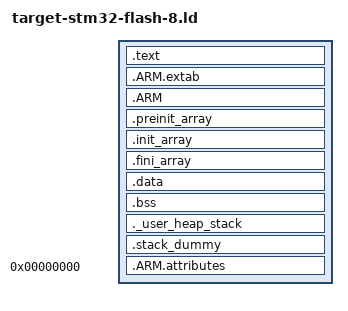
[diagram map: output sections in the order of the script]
/* Linker script to configure memory regions. 
 * Need modifying for a specific board. 
 *   FLASH.ORIGIN: starting address of flash
 *   FLASH.LENGTH: length of flash
 *   RAM.ORIGIN: starting address of RAM bank 0
 *   RAM.LENGTH: length of RAM bank 0
 */


/* Linker script to place sections and symbol values. Should be used together
 * with other linker script that defines memory regions FLASH and RAM.
 * It references following symbols, which must be defined in code:
 *   Reset_Handler : Entry of reset handler
 * 
 * It defines following symbols, which code can use without definition:
 *   __exidx_start
 *   __exidx_end
 *   __copy_table_start__
 *   __copy_table_end__
 *   __zero_table_start__
 *   __zero_table_end__
 *   __etext
 *   __data_start__
 *   __preinit_array_start
 *   __preinit_array_end
 *   __init_array_start
 *   __init_array_end
 *   __fini_array_start
 *   __fini_array_end
 *   __data_end__
 *   __bss_start__
 *   __bss_end__
 *   __end__
 *   end
 *   __HeapLimit
 *   __StackLimit
 *   __StackTop
 *   __stack
 */

ENTRY(Reset_Handler)

/* Highest address of the user mode stack */
_estack = 0x20020000;    /* end of 128K RAM on AHB bus*/

/* Generate a link error if heap and stack don't fit into RAM */
_Min_Heap_Size = 0;      /* required amount of heap  */
_Min_Stack_Size = 0x400; /* required amount of stack */

/* Define output sections */
SECTIONS
{
  /* The program code and other data goes into FLASH */
  .text :
  {
    . 	= ALIGN(8);
	KEEP(*(.isr_vector))
        *(.text)           /* .text sections (code) */

        KEEP (*(.init))
        KEEP (*(.fini))

	/* .ctors */
	*crtbegin.o(.ctors)
	*crtbegin?.o(.ctors)
	*(EXCLUDE_FILE(*crtend?.o *crtend.o) .ctors)
	*(SORT(.ctors.*))
	*(.ctors)

	/* .dtors */
 	*crtbegin.o(.dtors)
 	*crtbegin?.o(.dtors)
 	*(EXCLUDE_FILE(*crtend?.o *crtend.o) .dtors)
 	*(SORT(.dtors.*))
 	*(.dtors)


        *(.rodata*)        /* .rodata* sections (constants, strings, etc.) */
        KEEP(*(.eh_frame*))

    . = ALIGN(8);
    _etext = .;        /* define a global symbols at end of code */
  } >FLASH


   .ARM.extab   : { *(.ARM.extab* .gnu.linkonce.armextab.*) } >FLASH
    .ARM : {
    __exidx_start = .;
      *(.ARM.exidx*)
      __exidx_end = .;
    } >FLASH

  .preinit_array     :
  {
    PROVIDE_HIDDEN (__preinit_array_start = .);
    KEEP (*(.preinit_array*))
    PROVIDE_HIDDEN (__preinit_array_end = .);
  } >FLASH
  .init_array :
  {
    PROVIDE_HIDDEN (__init_array_start = .);
    KEEP (*(SORT(.init_array.*)))
    KEEP (*(.init_array*))
    PROVIDE_HIDDEN (__init_array_end = .);
  } >FLASH
  .fini_array :
  {
    PROVIDE_HIDDEN (__fini_array_start = .);
    KEEP (*(.fini_array*))
    KEEP (*(SORT(.fini_array.*)))
    PROVIDE_HIDDEN (__fini_array_end = .);
  } >FLASH

  /* used by the startup to initialize data */
  _sidata = .;

  /* Initialized data sections goes into RAM, load LMA copy after code */
  .data : AT ( _sidata )
  {
    . = ALIGN(8);
    __data_start__ = .;        /* create a global symbol at data start */
    *(vtable)    
    *(.data*)          /* .data* sections */


	KEEP(*(.jcr*))
    . = ALIGN(8);
    __data_end__ = .;        /* define a global symbol at data end */
  } >SRAM

  /* Uninitialized data section */
  . = ALIGN(4);
  .bss :
  {
    /* This is used by the startup in order to initialize the .bss secion */
    __bss_start__ = .;
    *(.bss*)
    *(COMMON)
    . = ALIGN(8);
    __bss_end__ = .;
  } >SRAM

  /* User_heap_stack section, used to check that there is enough RAM left */
  ._user_heap_stack :
  {
    . = ALIGN(8);
    PROVIDE ( end = . );
    PROVIDE ( _end = . );
		*(.heap*)    
    . = . + _Min_Heap_Size;
    . = . + _Min_Stack_Size;
    . = ALIGN(8);
  } >SRAM


	/* .stack_dummy section doesn't contains any symbols. It is only
	 * used for linker to calculate size of stack sections, and assign
	 * values to stack symbols later */
	.stack_dummy (COPY):
	{
		*(.stack*)
	} > SRAM

	/* Set stack top to end of RAM, and stack limit move down by
	 * size of stack_dummy section */
	__StackTop = ORIGIN(SRAM) + LENGTH(SRAM);
	__StackLimit = __StackTop - SIZEOF(.stack_dummy);
	PROVIDE(__stack = __StackTop);
	
	/* Check if data + heap + stack exceeds RAM limit */
/*	ASSERT(__StackLimit >= __HeapLimit, "region SRAM overflowed with stack")*/
	
	
  /* MEMORY_bank1 section, code must be located here explicitly            */
  /* Example: extern int foo(void) __attribute__ ((section (".mb1text"))); */
  /* Remove information from the standard libraries */
  /DISCARD/ :
  {
    libc.a ( * )
    libm.a ( * )
    libgcc.a ( * )
  }

  .ARM.attributes 0 : { *(.ARM.attributes) }
}
